# vexriscv_vitis register map
Vendor: fugafuga.org; Series: vexriscv; File version: 0.1
VexRiscv implemented on Alveo U50 Vitis Platform
Registers are 32-bit, read-write, reset 0x0 unless marked. A register's access mark holds for its fields unless they carry their own. Offsets are from the block's base; lines under a group give offsets from that group; [hi:lo] are bit positions; {n}, {i} and the like mark numbered series; 'fields as' and 'values as' point back to an identical list; <NAME> marks a mode.

## Memory map
0x40000000 GPIO
0x40010000 UART — 16550 compatible UART

## GPIO
Base 0x40000000
0x00 DATA
0x04 TRI reset 0xFFFFFFFF

## UART — 16550 compatible UART
Base 0x40010000
0x1000 THR
  [7:0] THR wo range 0x00..0xff
0x1000 RBR
  [7:0] RBR ro
0x1000 DLL
  [7:0] DLL range 0x00..0xff
0x1004 DLM
  [7:0] DLM range 0x00..0xff
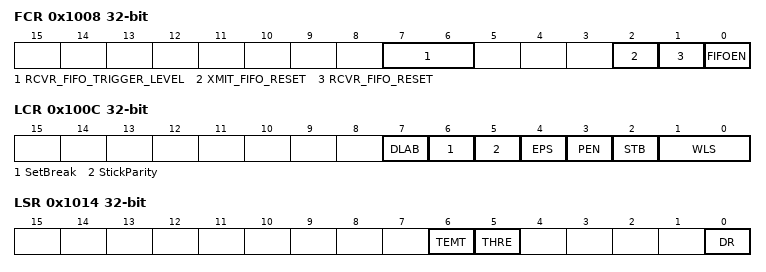
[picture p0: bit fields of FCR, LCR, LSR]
0x1008 FCR
  [7:6] RCVR_FIFO_TRIGGER_LEVEL
    0=OneByte; 1=FourBytes; 2=EightBytes; 3=FourteenBytes
  [2] XMIT_FIFO_RESET
    1=reset; 0=none
  [1] RCVR_FIFO_RESET
    1=reset; 0=none
  [0] FIFOEN
    1=enable; 0=disable
0x100C LCR
  [7] DLAB
    1=enable; 0=disable
  [6] SetBreak
  [5] StickParity
  [4] EPS
  [3] PEN
  [2] STB
    0=One; 1=TwoOrOnePointFive
  [1:0] WLS
    0=Five; 1=Six; 2=Seven; 3=Eight
0x1014 LSR
  [6] TEMT ro, [5] THRE ro, [0] DR ro
